# w600 register map
File version: v0.1
Registers are 32-bit, read-write, reset 0x0 unless marked. A register's access mark holds for its fields unless they carry their own. Offsets are from the block's base; lines under a group give offsets from that group; [hi:lo] are bit positions; {n}, {i} and the like mark numbered series; 'fields as' and 'values as' point back to an identical list; <NAME> marks a mode.

## Memory map
0x40000200 spi size 0x100
0x40000400 dma size 0x200
0x40000600 pmu size 0x100 — Power Managent Unit
0x40000600 rtc size 0x100 — real time
0x40002200 rsa size 0x700
0x40003200 crypto size 0x200 — GPSEC
0x40010000 i2c size 0x200
0x40010800 uart0 size 0x200
0x40010A00 uart1 size 0x200
0x40010C00 gpioa size 0x200
0x40010E00 timer size 0x200
0x40011000 watchdog size 0x200
0x40011200 gpiob size 0x200 — GPIOA
0x40011800 pwm size 0x200
0x40011A00 i2s size 0x200
0x40011C00 7816 size 0x200 — 7861/UART2
0x40013C00 rst size 0x1FFEC400 — Reset

## crypto — GPSEC
Base 0x40003200
0x00 src_addr — RC4/SHA1/AES/DES/3DES/CRC/MD5 复用源地址
0x04 dest_addr — RC4/AES/DES/3DES 复用目的地址
0x08 gpsec_cfg — 通用硬件加密模块配置寄存器
  [22:21] sub_mode — 算法类型子模式选择：
    0=DES/AES 密码算法的ECB 模式，可复用 CRC 算法的 CRC8 模式; 1=3DES/AES 密码算法的 CBC，可复用 CRC 算法的CRC16_0 模式; 2=AES 密码算法的CTR 模式，可复用 CRC 算法的CRC16_1 模式; 3=CRC 算法的CRC32
  [18:16] cypher_mode
    0=RSV; 1=RC4; 2=SHA1; 3=AES; 4=DES; 5=3DES; 6=CRC; 7=MD5
  [0] reserved — 保留
  [0] rng_start
    0=不启动RNG; 1=启动RNG
  [0] rng_load_seed — 硬件自动清 0
    0=随机数发生器会默认以零为种子，产生相应位数的随机数; 1=种子加载完成以后开始生成随机数
  [0] rng_switch — 控制生成随机数的位数，
    0=16 位; 1=32 位
  [0] des_soft_reset
    0=不产生软复位且不改变当前状态; 1=加密算法被软件复位为初始状态
  [0] aes_soft_reset — aes 软复位完成后硬件自动清 0
    0=不产生软复位且不改变当前状态; 1=加密算法被软件复位为初始状态
  [0] rc4_soft_reset
    0=不产生软复位且不改变当前状态; 1=加密算法被软件复位为初始状态
  [0] crc_datarev
    0=CRC 输入数据不反向; 1=CRC 输入数据反向
  [0] crc_chksrev
    0=CRC 输出结果不反向; 1=CRC 输出结果反向
  [0] encrypt_decrypt
    0=加密; 1=解密
  [0] gpsec_int_mask
    0=不屏蔽加/解密完成中断; 1=屏蔽加/解密完成中断
  [15:0] total_byte — 总共需要加解密操作的byte 个数。
0x0C gpsec_ctrl — 通用硬件加密模块控制寄存器
  [31:2] reserved — 保留
  [0] sec_stop — 停止当前正在进行的加解密操作
    0=无效; 1=加/解密停止
  [0] sec_strt
    0=不启动加/解密; 1=启动加/解密
0x10 key00 — Key0 低 32 位第一个输入key （RC4/AES/DES/3DES），复用 CRC Ci
0x14 key01 — Key0 高 32 位第一个输入key （RC4/AES/DES/3DES）
0x18 key10 — Key1 低 32 位第二个输入key （RC4/AES//3DES）
0x1C key11 — Key1 高 32 位第二个输入key （RC4/AES//3DES）
0x20 key20 — Key2 低 32 位第三个输入key（3DES）， 复用iv1 低 32 位输入初始向量（AES）
0x24 key21 — Key2 高 32 位第三个输入key（3DES）， 复用iv1 高 32 位输入初始向量（AES）
0x28 iv00 — IV0 低 32 位输入初始向量 （AES/DES/3DES）
0x2C iv01 — IV0 高 32 位输入初始向量 （AES/DES/3DES）
0x30 gpsec_sts — 通用硬件加密模块状态寄存器
  [31:17] reserved — 保留
  [0] int_flag — 软件写 1 清零
    0=不产生加/解密完成中断; 1=产生加/解密完成中断
  [15:0] transfer_cnt ro — 当前加密完成的字节个数。 每次重新开启加解密时清 0，并重新开始计数。
0x34 sha1-digest0 reset 0x67452301 — sha1-digest0/MD5-digest0
0x38 sha1-digest1 reset 0xEFCDAB89 — sha1-digest1/MD5-digest1
0x3C sha1-digest2 reset 0x98BADCFE — sha1-digest2/MD5-digest2
0x40 sha1-digest3 reset 0x10325476 — sha1-digest3/MD5-digest3
0x44 sha1-digest4 reset 0xC3D2E1F0 — sha1-digest4/CRC
0x48 rng_result — RNG 输出

## dma
Base 0x40000400
0x00 int_mask reset 0xFFFF — 设置需要屏蔽的DMA 中断
  [31:16] reserved — 保留
  [0] channel{n}_transfer_done (n=0..7) — 中断屏蔽，高有效。
  [0] channel{n}_burst_done (n=0..7) — 中断屏蔽，高有效。
0x04 int_src — 指示当前DMA 的中断状态
  [31:16] reserved — 保留
  [0] channel{n}_transfer_done (n=0..7) — 中断状态，写 1 清 0。DMA 传输完成产生中断。
  [0] channel{n}_burst_done (n=0..7) — 中断状态，写 1 清 0。DMA burst 完成产生中断。
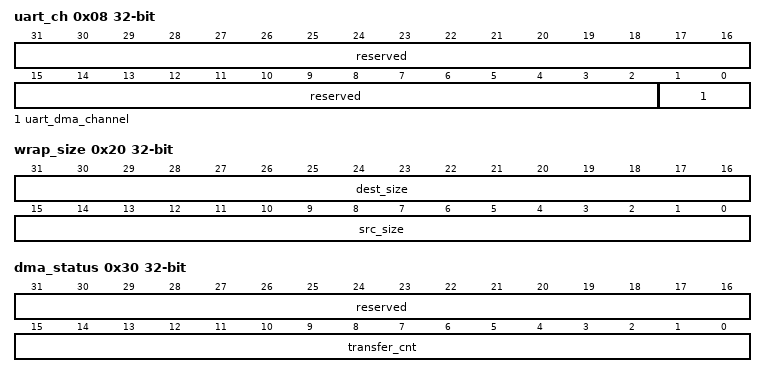
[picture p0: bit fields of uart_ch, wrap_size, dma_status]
0x08 uart_ch — UART 外设时选择哪个UART
  [31:2] reserved — 保留
  [1:0] uart_dma_channel — 选择：
    0=: uart0 模块dma 通道 接入dma; 1=: uart1 模块dma 通道 接入dma; 2=: uart2/7816 模块dma 通道 接入dma; 3=: 保留
0x10 src_addr — DMA 传输的源地址
  [31:0] src_addr — 非循环模式下，DMA 搬运的源地址，外设地址或内存地址
0x14 dest_addr — DMA 传输的目的地址
  [31:0] dest_addr — 非循环模式下，DMA 搬运的目的地址，外设地址或内存地址
0x18 src_wrap_addr — 循环模式下DMA 传输源地址
  [31:0] src_wrap_addr — 循环模式下，DMA 搬运的源地址的起始地址，外设地址或内存地址
0x1C dest_wrap_addr — 循环模式下DMA 传输目的地址
  [31:0] dest_wrap_addr — 循环模式下，DMA 搬运的目的地址的起始地址，外设地址或内存地址
0x20 wrap_size — 循环模式下DMA 循环边界
  [31:16] dest_size — 循环模式下，DMA 目的地址循环长度。 DMA 从起始地址依次递增搬运数据，当搬运数据字节数达到此设定值之后，会跳转到循环起始地址，从起始地址开始继续搬运数据
  [15:0] src_size — 循环模式下，DMA 源地址循环长度。
0x24 chnl_ctrl — 当前通道DMA 启动和停止
  [31:2] reserved — 保留
  [0] dma_stop — 停止dma 操作，高有效。 DMA 会在完成当前burst 操作后停止，并同时清除chnl_on。软件应根据chnl_on 为 0 确定dma 已经完全停止。
  [0] chnl_on — 启动当前通道DMA 转换，高有效。 Dma 完成后转换或设置停止后，自动清 0。
0x28 dma_mode — 设置DMA 的工作方式
  [31:7] reserved — 保留
  [5:2] dma_sel — 外设传输时，选择当前DMA 通道的外设类型。 16 个dma_req 的选择。
    0=uart rx dma req; 1=uart tx dma req; 2=pwm_cap0_req; 3=pwm_cap1_req; 4=LS_SPI rx dma req; 5=LS_SPI tx dma req; {v}=SD_ADC chnl{v-6} req (v=6..9); 10=dma_sel_a (SD_ADC chnl4 req); 11=dma_sel_b (SD_ADC chnl5 req); 12=dma_sel_c (SD_ADC chnl6 req); 13=dma_sel_d (SD_ADC chnl7 req); 14=dma_sel_e (: I2S RX req); 15=dma_sel_f (: I2S TX req)
  [0] chain_link_en — 链表方式下有效，表示 dma 在处理完第一个链表后，是否继续读取和处理后续链表。如果为 1，则更新链表中的next_desc_addr，并继续读取下一个链表，直到链表中 vld 为 0；如果为 0，则处理完成当前链表后即停止。
  [0] chain_mode
    0=使用普通模式; 1=使用链表模式
  [0] dma_mode
    0=软件方式。; 1=硬件方式。
0x2C dma_ctrl — 设置DMA 传输数据流
  [31:24] reserved — 保留
  [23:8] total_byte — 总共需要操作的byte 个数。需要与data_size 配置相一致，即若果为字操作，则应该为配置为 4 的整数倍；如果为半字操作，则应该配置为 2 的整数倍。
  [6:5] data_size — 设置DMA 的搬运单位
    0=byte; 1=half_word; 2=word; 3=保留
  [4:3] dest_addr_inc
    0=每次操作后目的地址不变；; 1=每次操作后目的地址自动累加。; 2=保留; 3=循环操作，每次操作后目的地址自动累加,到达定义的循环边界跳转到循环起始地址。
  [2:1] src_addr_inc
    0=每次操作后源地址不变；; 1=每次操作后源地址自动累加。; 2=保留; 3=循环操作，每次操作后源地址自动累加,到达定义的循环边界跳转到循环起始地址。
  [0] burst_size — 设置DMA 每次搬运多少个单位的数据 当最后一次burst 大小超过剩余传输的个数时，使用burst 大小为剩余数据的大小。
    0=burst 为 1; 1=burst 为 4
  [0] auto_reload — 当完成当前DMA 搬运后，自动按当前DMA 配置重新下一次DMA 搬运。
0x30 dma_status ro — 获取当前已传输的字节数
  [31:16] reserved — 保留
  [15:0] transfer_cnt rw — 当前传输的字节个数。 每次重新开启dma（chnl_on 置 1）清 0，并重新开始计数。
0x34 desc_addr — DMA 链表地址入口地址设置
  [31:0] desc_addr — 链表使能时，作为链表的入口地址。每传输完成一次链表后，将下一个链表的基地址更新至此寄存器。
0x38 cur_dest_addr ro — 当前DMA 操作的地址
  [31:0] current_dest_addr — 当前DMA 操作目的地址。 当软件停止dma 时，可以通过查看此寄存器获悉dma 将要操作的目的地址。
